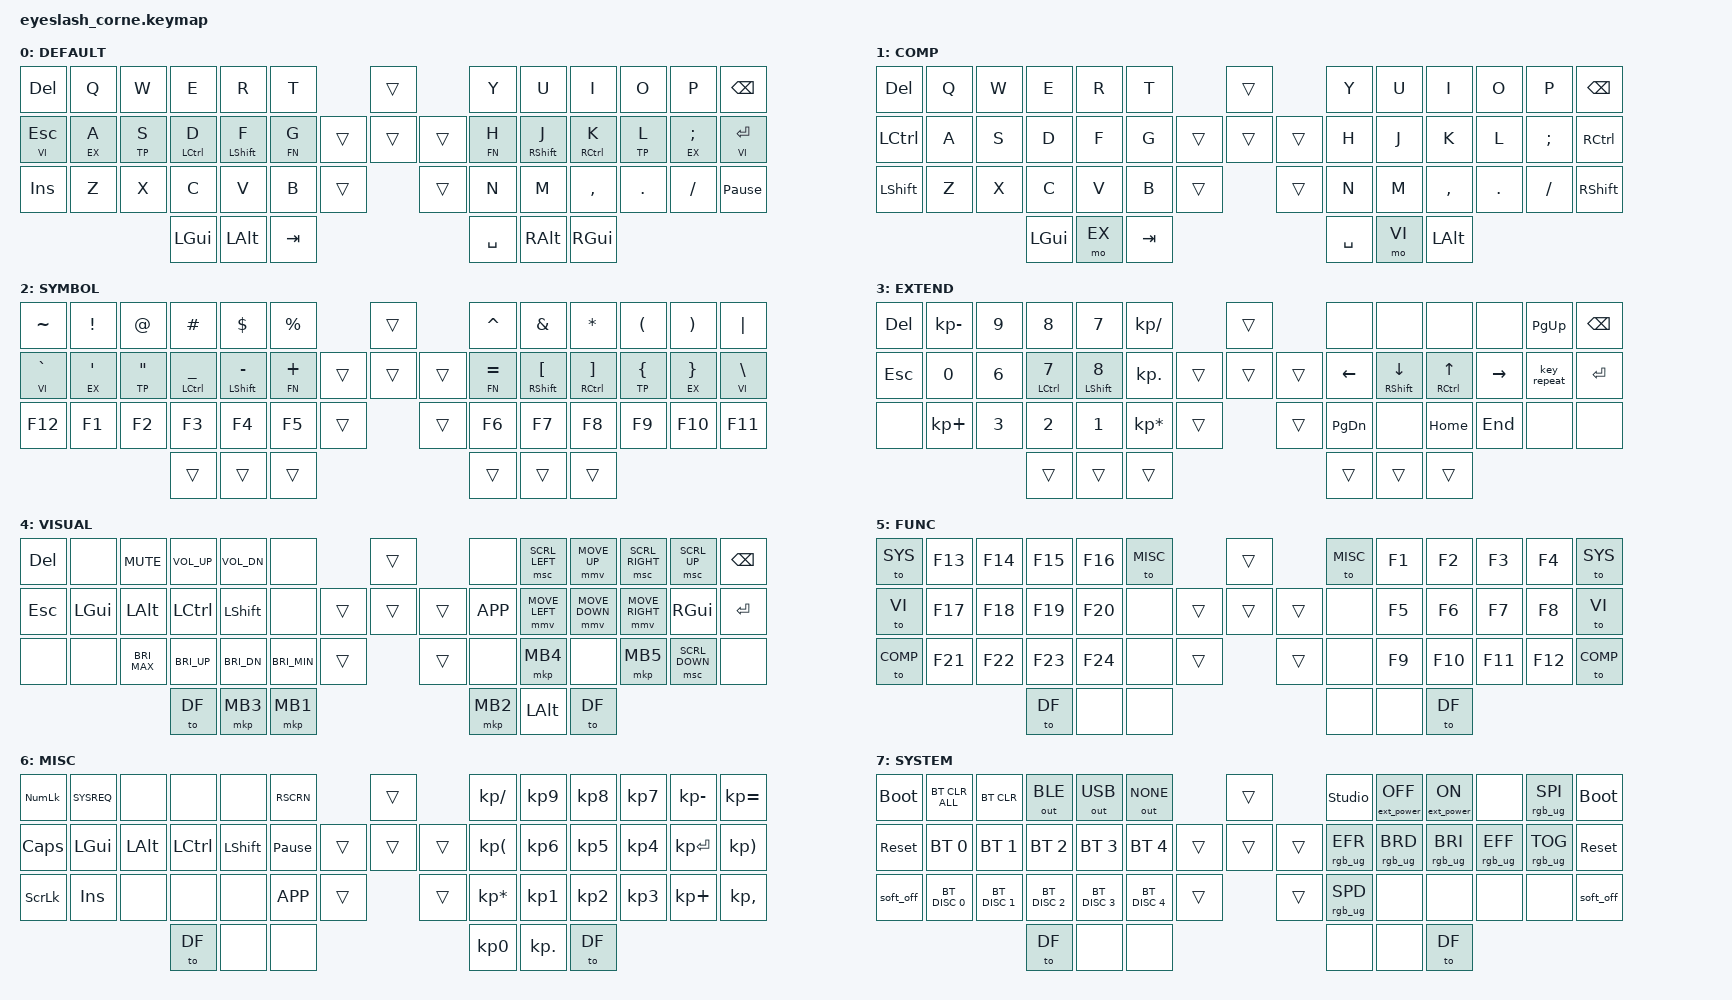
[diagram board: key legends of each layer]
#define ZMK_POINTING_DEFAULT_MOVE_VAL 1200  // 600
#define ZMK_POINTING_DEFAULT_SCRL_VAL 25   // 10

#include <zephyr/dt-bindings/input/input-event-codes.h>
#include <behaviors.dtsi>
#include <dt-bindings/zmk/keys.h>
#include <dt-bindings/zmk/pointing.h>

#include <dt-bindings/zmk/bt.h>
#include <dt-bindings/zmk/outputs.h>

#include <dt-bindings/zmk/rgb.h>
#include <input/processors.dtsi>
#include <behaviors/runtime-sensor-rotate.dtsi>
#include <dt-bindings/zmk/ext_power.h>

#define DF   0 // DEFAULT
#define COMP 1 // COMPATIBLE
#define TP   2 // TOP & SYMBOL
#define EX   3 // EXTEND
#define VI   4 // VISUAL
#define FN   5 // FUNCTION
#define MISC 6 // MISCELLANEOUS
#define SYS  7 // SYSTEM

&i2c0_default {
    #binding-cells = <0>;
};

&mmv_input_listener { input-processors = <&zip_xy_scaler 2 1>; };

&msc_input_listener { input-processors = <&zip_scroll_scaler 2 1>; };

&msc {
    acceleration-exponent = <1>;      // 0
    time-to-max-speed-ms = <100>;       // 300
    delay-ms = <0>;                   // 0
};

&mmv {
    time-to-max-speed-ms = <500>;
    acceleration-exponent = <1>;
    trigger-period-ms = <16>;
};

// &soft_off { hold-time-ms = <2000>; };

&caps_word {
    continue-list = UNDERSCORE MINUS BSPC DEL>; // INS
}

/ {
    behaviors {
        rsr_vol: rsr_vol {
            compatible = "zmk,behavior-runtime-sensor-rotate";
            #sensor-binding-cells = <0>;
            tap-ms = <5>;
            cw-binding = <&kp C_VOL_UP>;
            ccw-binding = <&kp C_VOL_DN>;
        };

        rsr_trans: rsr_trans {
            compatible = "zmk,behavior-runtime-sensor-rotate";
            #sensor-binding-cells = <0>;
            tap-ms = <0>;
        };
    };

    rgb_encoder: rgb_encoder {
        compatible = "zmk,behavior-sensor-rotate";
        #sensor-binding-cells = <0>;
        bindings = <&rgb_ug RGB_BRI>, <&rgb_ug RGB_BRD>;
    };

    scroll_encoder: scroll_encoder {
        compatible = "zmk,behavior-sensor-rotate";
        #sensor-binding-cells = <0>;
        bindings = <&msc SCRL_DOWN>, <&msc SCRL_UP>;
        tap-ms = <100>;
    };

// +---+---+---+---+---+---+           +---+       +---+---+---+---+---+---+
// |0   1   2   3   4   5  |           |6  |       |7   8   9   10  11  12 |
// +---+---+---+---+---+---+       +---+---+---+   +---+---+---+---+---+---+
// |13  14  15  16  17  18 |       |19  20  21 |   |22  23  24  25  26  27 |
// +---+---+---+---+---+---+   +---+---+---+---+   +---+---+---+---+---+---+
// |28  29  30  31  32  33 |   |34 |   |35 |       |36  37  38  39  40  41 |
// +---+---+---+---+---+---+   +---+   +---+       +---+---+---+---+---+---+
//             |42  43  44 |                       |45  46  47 |
//             +---+---+---+                       +---+---+---+

    combos {
        compatible = "zmk,combos";

        combo_lang {
            layers = <0>; timeout-ms = <50>;
            key-positions = <44 45>;
            bindings = <&kp LG(SPACE)>;
        };
        combo_capsword {
            layers = <0>; timeout-ms = <50>;
            key-positions = <43 46>;
            bindings = <&caps_word>;
        };

        combo_0 {
            layers = <0>; timeout-ms = <50>;
            key-positions = <14 26>;
            bindings = <&kp N0>;
        };
        combo_1 {
            layers = <0>; timeout-ms = <50>;
            key-positions = <32 37>;
            bindings = <&kp N1>;
        };
        combo_2 {
            layers = <0>; timeout-ms = <50>;
            key-positions = <31 38>;
            bindings = <&kp N2>;
        };
        combo_3 {
            layers = <0>; timeout-ms = <50>;
            key-positions = <30 39>;
            bindings = <&kp N3>;
        };
        combo_4 {
            layers = <0>; timeout-ms = <50>;
            key-positions = <17 23>;
            bindings = <&kp N4>;
        };
        combo_5 {
            layers = <0>; timeout-ms = <50>;
            key-positions = <16 24>;
            bindings = <&kp N5>;
        };
        combo_6 {
            layers = <0>; timeout-ms = <50>;
            key-positions = <15 25>;
            bindings = <&kp N6>;
        };
        combo_7 {
            layers = <0>; timeout-ms = <50>;
            key-positions = <4 8>;
            bindings = <&kp N7>;
        };
        combo_8 {
            layers = <0>; timeout-ms = <50>;
            key-positions = <3 9>;
            bindings = <&kp N8>;
        };
        combo_9 {
            layers = <0>; timeout-ms = <50>;
            key-positions = <2 10>;
            bindings = <&kp N9>;
        };

    };

    keymap {
        compatible = "zmk,keymap";

        default_layer {
            display-name = "DEFAULT"; // mt: Mod Tap
            bindings = <
//---------+----------+----------+----------  +----------  +----------|  |-------|-------|-------|-------|  |----------+----------  +----------  +----------+----------  +----------|
&kp DEL    &kp Q      &kp W      &kp E        &kp R        &kp T                         &trans             &kp Y      &kp U        &kp I        &kp O      &kp P        &kp BSPC
//---------+----------+----------+----------  +----------  +----------|  |-------|-------|-------|-------|  |----------+----------  +----------  +----------+----------  +----------|
&lt VI ESC  &lt EX A  &lt TP S   &mt LCTRL D  &mt LSHFT F  &lt FN G              &trans  &trans  &trans     &lt FN H   &mt RSHFT J  &mt RCTRL K  &lt TP L   &lt EX SEMI  &lt VI RET
//---------+----------+----------+----------  +----------  +----------|  |-------|-------|-------|-------|  |----------+----------  +----------  +----------+----------  +----------|
&kp INS    &kp Z      &kp X      &kp C        &kp V        &kp B         &trans          &trans             &kp N      &kp M        &kp COMMA    &kp DOT    &kp FSLH     &kp PAUSE_BREAK
//---------+----------+----------+----------  +----------  +----------|  |-------|-------|-------|-------|  |----------+----------  +----------  +----------+----------  +----------|
                                 &kp LGUI     &kp LALT     &kp TAB                                          &kp SPACE  &kp RALT     &kp RGUI
//---------+----------+----------+----------  +----------  +----------|  |-------|-------|-------|-------|  |----------+----------  +----------  +----------+----------  +----------|
            >;
            sensor-bindings = <&rsr_vol &rsr_trans>;
        };

        comp_layer {
            display-name = "COMP";
            bindings = <
//---------+----------+----------+----------+----------+----------|  |-------|-------|-------|-------|  |----------+----------+----------+----------+----------+----------|
&kp DEL    &kp Q      &kp W      &kp E      &kp R      &kp T                         &trans             &kp Y      &kp U      &kp I      &kp O      &kp P      &kp BSPC
//---------+----------+----------+----------+----------+----------|  |-------|-------|-------|-------|  |----------+----------+----------+----------+----------+----------|
&kp LCTRL  &kp A      &kp S      &kp D      &kp F      &kp G                 &trans  &trans  &trans     &kp H      &kp J      &kp K      &kp L      &kp SEMI   &kp RCTRL
//---------+----------+----------+----------+----------+----------|  |-------|-------|-------|-------|  |----------+----------+----------+----------+----------+----------|
&kp LSHFT  &kp Z      &kp X      &kp C      &kp V      &kp B         &trans          &trans             &kp N      &kp M      &kp COMMA  &kp DOT    &kp FSLH   &kp RSHFT
//---------+----------+----------+----------+----------+----------|  |-------|-------|-------|-------|  |----------+----------+----------+----------+----------+----------|
                                 &kp LGUI   &mo EX     &kp TAB                                          &kp SPACE  &mo VI     &kp LALT
//---------+----------+----------+----------+----------+----------|  |-------|-------|-------|-------|  |----------+----------+----------+----------+----------+----------|
            >;
            sensor-bindings = <&rsr_vol &rsr_trans>;
        };

        symbol_layer {
            display-name = "SYMBOL";
            bindings = <
//---------   +---------- +---------- +----------      +----------      +----------|  |-------|-------|-------|-------|  |----------   +----------     +----------     +----------  +----------  +----------|
&kp TILDE     &kp EXCL    &kp AT      &kp HASH         &kp DLLR         &kp PRCNT                     &trans             &kp CARET     &kp AMPS        &kp ASTRK       &kp LPAR     &kp RPAR     &kp PIPE
//---------   +---------- +---------- +----------      +----------      +----------|  |-------|-------|-------|-------|  |----------   +----------     +----------     +----------  +----------  +----------|
&lt VI GRAVE  &lt EX SQT  &lt TP DQT  &mt LCTRL UNDER  &mt LSHFT MINUS  &lt FN PLUS           &trans  &trans  &trans     &lt FN EQUAL  &mt RSHFT LBKT  &mt RCTRL RBKT  &lt TP LBRC  &lt EX RBRC  &lt VI BSLH
//---------   +---------- +---------- +----------      +----------      +----------|  |-------|-------|-------|-------|  |----------   +----------     +----------     +----------  +----------  +----------|
&kp F12       &kp F1      &kp F2      &kp F3           &kp F4           &kp F5        &trans          &trans             &kp F6        &kp F7          &kp F8          &kp F9       &kp F10      &kp F11
//---------   +---------- +---------- +----------      +----------      +----------|  |-------|-------|-------|-------|  |----------   +----------     +----------     +----------  +----------  +----------|
                          &trans      &trans           &trans                                                            &trans        &trans          &trans
//---------   +---------- +---------- +----------      +----------      +----------|  |-------|-------|-------|-------|  |----------   +----------     +----------     +----------  +----------  +----------|
            >;
            sensor-bindings = <&rsr_vol &rsr_trans>;
        };

        extend_layer {
            display-name = "EXTEND";
            bindings = <
//---------+----------   +----------+----------   +----------   +----------|     |-------|-------|-------|-------|  |----------+----------      +----------   +----------+----------  +----------|
&kp DEL    &kp KP_MINUS  &kp N9     &kp N8        &kp N7        &kp KP_DIVIDE                    &trans             &none      &none            &none         &none      &kp PG_UP    &kp BSPC
//---------+----------   +----------+----------   +----------   +----------|     |-------|-------|-------|-------|  |----------+----------      +----------   +----------+----------  +----------|
&kp ESC    &kp N0        &kp N6     &mt LCTRL N7  &mt LSHFT N8  &kp KP_DOT               &trans  &trans  &trans     &kp LEFT   &mt RSHFT DOWN   &mt RCTRL UP  &kp RIGHT  &key_repeat  &kp RET
//---------+----------   +----------+----------   +----------   +----------|     |-------|-------|-------|-------|  |----------+----------      +----------   +----------+----------  +----------|
&none      &kp KP_PLUS   &kp N3     &kp N2        &kp N1        &kp KP_MULTIPLY  &trans          &trans             &kp PG_DN  &none            &kp HOME      &kp END    &none        &none
//---------+----------   +----------+----------   +----------   +----------|     |-------|-------|-------|-------|  |----------+----------      +----------   +----------+----------  +----------|
                                    &trans        &trans        &trans                                                         &trans           &trans        &trans
//---------+----------   +----------+----------   +----------   +----------|     |-------|-------|-------|-------|  |----------+----------      +----------   +----------+----------  +----------|
            >;
            sensor-bindings = <&rsr_vol &rsr_trans>;
        };

        visual_layer {
            display-name = "VISUAL";
            bindings = < // mmv: Mouse Move; mkp: Mouse Key Press; msc: Mouse Scroll
//---------+----------+----------    +----------   +----------   +----------|   |-------|-------|-------|-------|  |----------+----------     +----------     +----------      +----------     +----------|
&kp DEL    &none      &kp C_MUTE     &kp C_VOL_UP  &kp C_VOL_DN  &none                          &trans             &none      &msc SCRL_LEFT  &mmv MOVE_UP    &msc SCRL_RIGHT  &msc SCRL_UP    &kp BSPC
//---------+----------+----------    +----------   +----------   +----------|   |-------|-------|-------|-------|  |----------+----------     +----------     +----------      +----------     +----------|
&kp ESC    &kp LGUI   &kp LALT       &kp LCTRL     &kp LSHFT     &none                  &trans  &trans  &trans     &kp APP    &mmv MOVE_LEFT  &mmv MOVE_DOWN  &mmv MOVE_RIGHT  &kp RGUI        &kp RET
//---------+----------+----------    +----------   +----------   +----------|   |-------|-------|-------|-------|  |----------+----------     +----------     +----------      +----------     +----------|
&none      &none      &kp C_BRI_MAX  &kp C_BRI_UP  &kp C_BRI_DN  &kp C_BRI_MIN  &trans          &trans             &none      &mkp MB4        &none           &mkp MB5         &msc SCRL_DOWN  &none
//---------+----------+----------    +----------   +----------   +----------|   |-------|-------|-------|-------|  |----------+----------     +----------     +----------      +----------     +----------|
                                     &to DF        &mkp MB3      &mkp MB1                                                     &mkp MB2        &kp LALT        &to DF
//---------+----------+----------    +----------   +----------   +----------|   |-------|-------|-------|-------|  |----------+----------     +----------     +----------      +----------     +----------|
            >;
            sensor-bindings = <&rsr_vol &rsr_trans>;
        };

        func_layer {
            display-name = "FUNC";
            bindings = <
//---------+----------+----------+----------+----------+----------|  |-------|-------|-------|-------|  |----------+----------+----------+----------+----------+----------|
&to SYS    &kp F13    &kp F14    &kp F15    &kp F16    &to MISC                      &trans             &to MISC   &kp F1     &kp F2     &kp F3     &kp F4     &to SYS
//---------+----------+----------+----------+----------+----------|  |-------|-------|-------|-------|  |----------+----------+----------+----------+----------+----------|
&to VI     &kp F17    &kp F18    &kp F19    &kp F20    &none                 &trans  &trans  &trans     &none      &kp F5     &kp F6     &kp F7     &kp F8     &to VI
//---------+----------+----------+----------+----------+----------|  |-------|-------|-------|-------|  |----------+----------+----------+----------+----------+----------|
&to COMP   &kp F21    &kp F22    &kp F23    &kp F24    &none         &trans          &trans             &none      &kp F9     &kp F10    &kp F11    &kp F12    &to COMP
//---------+----------+----------+----------+----------+----------|  |-------|-------|-------|-------|  |----------+----------+----------+----------+----------+----------|
                                 &to DF     &none      &none                                            &none      &none      &to DF
//---------+----------+----------+----------+----------+----------|  |-------|-------|-------|-------|  |----------+----------+----------+----------+----------+----------|
            >;
            sensor-bindings = <&rsr_vol &rsr_trans>; // SYSREQ
        };

        misc_layer {
            display-name = "MISC";
            bindings = <
///---------  +---------- +----------+----------+----------+----------|     |-------|-------|-------|-------|  |----------      +---------- +----------   +----------+----------   +----------|
&kp KP_NLCK   &kp SYSREQ  &none      &none      &none      &kp RSCRN                        &trans             &kp KP_DIVIDE    &kp KP_N9   &kp KP_N8     &kp KP_N7  &kp KP_MINUS  &kp KP_EQUAL
///---------  +---------- +----------+----------+----------+----------|     |-------|-------|-------|-------|  |----------      +---------- +----------   +----------+----------   +----------|
&kp CAPS      &kp LGUI    &kp LALT   &kp LCTRL  &kp LSHFT  &kp PAUSE_BREAK          &trans  &trans  &trans     &kp KP_LPAR      &kp KP_N6   &kp KP_N5     &kp KP_N4  &kp KP_ENTER  &kp KP_RPAR
///---------  +---------- +----------+----------+----------+----------|     |-------|-------|-------|-------|  |----------      +---------- +----------   +----------+----------   +----------|
&kp SLCK      &kp INS     &none      &none      &none      &kp APP          &trans          &trans             &kp KP_MULTIPLY  &kp KP_N1   &kp KP_N2     &kp KP_N3  &kp KP_PLUS   &kp KP_COMMA
///---------  +---------- +----------+----------+----------+----------|     |-------|-------|-------|-------|  |----------      +---------- +----------   +----------+----------   +----------|
                                     &to DF     &none      &none                                               &kp KP_N0        &kp KP_DOT  &to DF
///---------  +---------- +----------+----------+----------+----------|     |-------|-------|-------|-------|  |----------      +---------- +----------   +----------+----------   +----------|
            >;
            sensor-bindings = <&rsr_vol &rsr_trans>;
        };

        system_layer { // rgb_ug: RGB Underglow; EFF: Effect forward; EFR: Effect reverse; EP: External Power
            display-name = "SYSTEM";
            bindings = <
//---------+----------     +----------    +----------    +----------    +----------|   |-------|-------|-------|-------|  |----------      +----------        +----------       +----------      +----------      +----------|
&bootloader&bt BT_CLR_ALL  &bt BT_CLR     &out OUT_BLE   &out OUT_USB   &out OUT_NONE                  &trans             &studio_unlock   &ext_power EP_OFF  &ext_power EP_ON  &none            &rgb_ug RGB_SPI  &bootloader
//---------+----------     +----------    +----------    +----------    +----------|   |-------|-------|-------|-------|  |----------      +----------        +----------       +----------      +----------      +----------|
&sys_reset &bt BT_SEL 0    &bt BT_SEL 1   &bt BT_SEL 2   &bt BT_SEL 3   &bt BT_SEL 4           &trans  &trans  &trans     &rgb_ug RGB_EFR  &rgb_ug RGB_BRD    &rgb_ug RGB_BRI   &rgb_ug RGB_EFF  &rgb_ug RGB_TOG  &sys_reset
//---------+----------     +----------    +----------    +----------    +----------|   |-------|-------|-------|-------|  |----------      +----------        +----------       +----------      +----------      +----------|
&soft_off  &bt BT_DISC 0   &bt BT_DISC 1  &bt BT_DISC 2  &bt BT_DISC 3  &bt BT_DISC 4  &trans          &trans             &rgb_ug RGB_SPD  &none              &none             &none            &none            &soft_off
//---------+----------     +----------    +----------    +----------    +----------|   |-------|-------|-------|-------|  |----------      +----------        +----------       +----------      +----------      +----------|
                                          &to DF         &none          &none                                             &none            &none              &to DF
//---------+----------     +----------    +----------    +----------    +----------|   |-------|-------|-------|-------|  |----------      +----------        +----------       +----------      +----------      +----------|
            >;
            sensor-bindings = <&rsr_vol &rsr_trans>; // RGB_ON RGB_OFF BT_NXT BT_PRE OUT_TOG; ext_power EP_TOG
        };

// TEMPLATE
/*         xxxxxx_layer { */
/*             display-name = "XXXXXX"; */
/*             bindings = < */
/* //---------+----------+----------+----------+----------+----------|  |-------|-------|-------|-------|  |----------+----------+----------+----------+----------+----------| */
/* &none      &none      &none      &none      &none      &none                         &trans             &none      &none      &none      &none      &none      &none  */
/* //---------+----------+----------+----------+----------+----------|  |-------|-------|-------|-------|  |----------+----------+----------+----------+----------+----------| */
/* &none      &none      &none      &none      &none      &none                 &trans  &trans  &trans     &none      &none      &none      &none      &none      &none  */
/* //---------+----------+----------+----------+----------+----------|  |-------|-------|-------|-------|  |----------+----------+----------+----------+----------+----------| */
/* &none      &none      &none      &none      &none      &none         &trans          &trans             &none      &none      &none      &none      &none      &none  */
/* //---------+----------+----------+----------+----------+----------|  |-------|-------|-------|-------|  |----------+----------+----------+----------+----------+----------| */
/*                                  &trans     &trans     &trans                                                      &trans     &trans     &trans */
/* //---------+----------+----------+----------+----------+----------|  |-------|-------|-------|-------|  |----------+----------+----------+----------+----------+----------| */
/*             >; */
/*             sensor-bindings = <&rsr_vol &rsr_trans>; */
/*         }; */

    };
};
